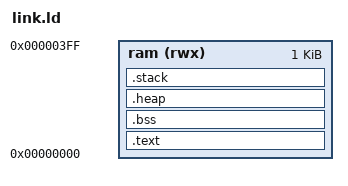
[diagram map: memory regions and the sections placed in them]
OUTPUT_FORMAT("elf32-littlearm", "elf32-littlearm", "elf32-littlearm")
OUTPUT_ARCH(arm)
SEARCH_DIR(.)

ENTRY(main)

MEMORY
{
  ram (rwx)  : ORIGIN = 0x00000000, LENGTH = 0x00000400
}

STACK_SIZE = 0x0FF;
HEAP_SIZE = 0x0FF;


SECTIONS
{
    .text :
    {
        _sfixed = .;
        *(.interp)
        *(.text)
    } > ram

    .bss (NOLOAD) :
    {
        . = ALIGN(4);
        _sbss = . ;
        _szero = .;
        *(.bss .bss.*)
        *(COMMON)
        . = ALIGN(4);
        _ebss = . ;
        _ezero = .;
    } > ram

    /* heap section */
    .heap (NOLOAD):
    {
        . = ALIGN(8);
         _sheap = .;
        . = . + HEAP_SIZE;
        . = ALIGN(8);
        _eheap = .;
    } > ram

    /* stack section */
    .stack (NOLOAD):
    {
        . = ALIGN(8);
        _sstack = .;
        . = . + STACK_SIZE;
        . = ALIGN(8);
        _estack = .;
    } > ram

    . = ALIGN(4);
    _end = . ;
    _ram_end_ = ORIGIN(ram) + LENGTH(ram) -1 ;
}
